# ucbbar_spike_bare_qemu register map
File version: 0.1
From ucbbar,spike-bare,qemu,model device generator
Registers are 32-bit, read-write, no defined reset value unless marked. A register's access mark holds for its fields unless they carry their own. Offsets are from the block's base; lines under a group give offsets from that group; [hi:lo] are bit positions; {n}, {i} and the like mark numbered series; 'fields as' and 'values as' point back to an identical list; <NAME> marks a mode.

## Memory map
0x00100000 sifive_test0_0 size 0x1000 — From sifive,test0,control peripheral generator
0x0C000000 riscv_plic0_0 size 0x4000000 — From riscv,plic0,control peripheral generator

## sifive_test0_0 — From sifive,test0,control peripheral generator
Base 0x00100000
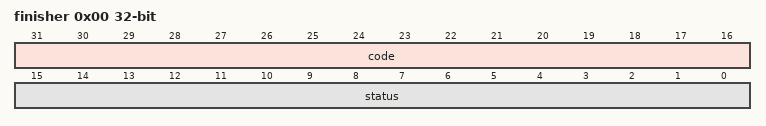
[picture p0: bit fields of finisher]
0x00 finisher — Test finisher register
  [31:16] code — Finisher code
  [15:0] status — Test status

## riscv_plic0_0 — From riscv,plic0,control peripheral generator
Base 0x0C000000
{0x0+4i} priority_{i} (i=1..53) — PRIORITY Register for interrupt id {i}
0x1000 pending_0 — PENDING Register for interrupt ids 31 to 0
0x1004 pending_1 — PENDING Register for interrupt ids 53 to 32
{0x2000+0x80*i} enable_0_{i} (i=0..3) — ENABLE Register for interrupt ids 31 to 0 for hart {i}
{0x2004+0x80*i} enable_1_{i} (i=0..3) — ENABLE Register for interrupt ids 53 to 32 for hart {i}
{0x200000+0x1000*i} threshold_{i} (i=0..3) — PRIORITY THRESHOLD Register for hart {i}
{0x200004+0x1000*i} claimplete_{i} (i=0..3) — CLAIM and COMPLETE Register for hart {i}
